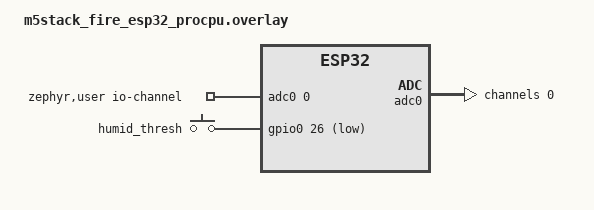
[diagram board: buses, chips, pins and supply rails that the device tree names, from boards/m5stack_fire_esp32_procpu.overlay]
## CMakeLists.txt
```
# Copyright (c) 2026 Lenka Koskova Triskova
#
# SPDX-License-Identifier: Apache-2.0
# https://www.apache.org/licenses/LICENSE-2.0

cmake_minimum_required(VERSION 3.20.0)

find_package(Zephyr REQUIRED HINTS $ENV{ZEPHYR_BASE})
project(humidity)

target_sources(app PRIVATE src/main.c)
```

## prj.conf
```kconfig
# Copyright (c) 2026 Lenka Koskova Triskova
#
# SPDX-License-Identifier: Apache-2.0
# https://www.apache.org/licenses/LICENSE-2.0

CONFIG_LOG=y
CONFIG_SHELL=y

# Unit Earth probe: no Zephyr sensor driver exists for it, so this reads
# the ADC and GPIO directly instead of going through CONFIG_SENSOR like
# 09-gyroscope does.
CONFIG_ADC=y

# Sampling thread publishes readings here; the logging thread is just
# one subscriber among however many you add.
CONFIG_ZBUS=y
```

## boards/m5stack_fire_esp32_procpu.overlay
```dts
/*
 * Copyright (c) 2026 Lenka Koskova Triskova
 *
 * SPDX-License-Identifier: Apache-2.0
 * https://www.apache.org/licenses/LICENSE-2.0
 */

/*
 * M5Stack "Unit Earth" analog soil/humidity probe, on Grove Port B:
 *
 *   - an analog reading on ADC1 channel 0 (Port B's D0 pin, GPIO36)
 *   - a digital wet/dry threshold output on Port B's D1 pin (&gpio0 26)
 *
 * Neither is defined by this board's own Zephyr devicetree - there is
 * no discrete sensor chip here (just a resistive probe plus a
 * comparator on the breakout board), so there is no Zephyr sensor
 * driver either: this is read directly via the ADC and GPIO APIs,
 * unlike 09-gyroscope's onboard MPU6886 which has a real driver.
 *
 * Per M5Stack's own official docs and ESP-IDF's adc_channel.h
 * (ADC1_CHANNEL_0_GPIO_NUM 36), Port B's D0 pin is GPIO36 = ADC1
 * channel 0.
 */

#include <zephyr/dt-bindings/adc/adc.h>
#include <zephyr/dt-bindings/input/input-event-codes.h>

/ {
	aliases {
		thresh = &humid_thresh;
	};

	zephyr,user {
		io-channels = <&adc0 0>;
	};

	/* "gpio-keys" is just the binding whose child-binding declares
	 * "gpios" as a phandle-array - a bare node with no compatible at
	 * all does not get that property type recognized, and
	 * GPIO_DT_SPEC_GET() then fails to compile. The input/key
	 * semantics of this binding are not used here - the pin is read
	 * directly as a plain GPIO in src/main.c, not through the input
	 * subsystem.
	 */
	humid_thresh_grp: humid_thresh_grp {
		compatible = "gpio-keys";

		humid_thresh: humid_thresh {
			/* ESP32's GPIO controller takes exactly one flags
			 * cell (#gpio-cells = <2>: pin, flags) - OR the
			 * flags together, don't list them as separate cells.
			 */
			gpios = <&gpio0 26 (GPIO_ACTIVE_LOW | GPIO_PULL_DOWN)>;
			/* Required by this binding's driver, but unused -
			 * this pin is read directly in src/main.c, never
			 * through the input subsystem.
			 */
			zephyr,code = <INPUT_KEY_9>;
		};
	};
};

&adc0 {
	compatible = "espressif,esp32-adc";
	status = "okay";
	#address-cells = <1>;
	#size-cells = <0>;

	channel0: channel@0 {
		status = "okay";
		reg = <0>;
		zephyr,gain = "ADC_GAIN_1_4";
		zephyr,reference = "ADC_REF_INTERNAL";
		zephyr,acquisition-time = <ADC_ACQ_TIME_DEFAULT>;
		/* Required - the ESP32 ADC driver rejects resolution 0,
		 * the default if left unset. 12-bit is this chip's max.
		 */
		zephyr,resolution = <12>;
	};
};

/* Not used by this app. */
&speaker {
	status = "disabled";
};
```

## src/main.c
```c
/*
 * Copyright (c) 2026 Lenka Koskova Triskova
 *
 * SPDX-License-Identifier: Apache-2.0
 * https://www.apache.org/licenses/LICENSE-2.0
 */

#include <zephyr/kernel.h>
#include <zephyr/device.h>
#include <zephyr/devicetree.h>
#include <zephyr/drivers/adc.h>
#include <zephyr/drivers/gpio.h>
#include <zephyr/zbus/zbus.h>
#include <zephyr/logging/log.h>

LOG_MODULE_REGISTER(main);

#if !DT_NODE_EXISTS(DT_PATH(zephyr_user)) || \
	!DT_NODE_HAS_PROP(DT_PATH(zephyr_user), io_channels)
#error "No suitable devicetree overlay specified - see boards/m5stack_fire_esp32_procpu.overlay"
#endif

#define SAMPLE_INTERVAL K_SECONDS(2)

/* Calibrate these against your own probe: watch the "raw=" value in the
 * log output in open air and in wet soil, and set these two to match.
 */
#define ADC_MIN_VALUE 830
#define ADC_MAX_VALUE 1940
#define PCT_MIN       0
#define PCT_MAX       100

struct humidity_msg {
	int16_t raw;
	int16_t percent;
	bool threshold_high;
};

/* The channel is shared between the sampling thread (publisher, below)
 * and whoever wants the readings (observers) - here just
 * humidity_log_sub, but any thread can later subscribe without the
 * sampling thread ever changing. Same template as 09-gyroscope.
 */
ZBUS_CHAN_DEFINE(humidity_chan,
		 struct humidity_msg,
		 NULL,
		 NULL,
		 ZBUS_OBSERVERS(humidity_log_sub),
		 ZBUS_MSG_INIT(0)
);

/* Subscriber, not listener: it gets its own thread and message queue,
 * so a slow or blocking reaction here can never stall the sampling
 * thread - see 09-gyroscope's README for why this is the default for
 * every observer in this course, sensors and actuators alike.
 */
ZBUS_SUBSCRIBER_DEFINE(humidity_log_sub, 4);

static void humidity_log_thread(void *p1, void *p2, void *p3)
{
	ARG_UNUSED(p1);
	ARG_UNUSED(p2);
	ARG_UNUSED(p3);

	const struct zbus_channel *chan;

	while (!zbus_sub_wait(&humidity_log_sub, &chan, K_FOREVER)) {
		struct humidity_msg msg;

		if (chan != &humidity_chan) {
			continue;
		}

		zbus_chan_read(&humidity_chan, &msg, K_MSEC(100));

		LOG_INF("humidity: %d%% (raw=%d, threshold %s)",
			msg.percent, msg.raw, msg.threshold_high ? "HIGH" : "LOW");
	}
}

#define HUMIDITY_LOG_STACK_SIZE 1024
#define HUMIDITY_LOG_PRIORITY   5

K_THREAD_DEFINE(humidity_log_tid, HUMIDITY_LOG_STACK_SIZE, humidity_log_thread,
		 NULL, NULL, NULL, HUMIDITY_LOG_PRIORITY, 0, 0);

static void humidity_sampling_thread(void *p1, void *p2, void *p3)
{
	ARG_UNUSED(p1);
	ARG_UNUSED(p2);
	ARG_UNUSED(p3);

	static const struct adc_dt_spec probe = ADC_DT_SPEC_GET(DT_PATH(zephyr_user));
	static const struct gpio_dt_spec thresh = GPIO_DT_SPEC_GET(DT_ALIAS(thresh), gpios);

	if (!adc_is_ready_dt(&probe)) {
		LOG_ERR("ADC device is not ready");
		return;
	}
	if (adc_channel_setup_dt(&probe) < 0) {
		LOG_ERR("Failed to set up ADC channel");
		return;
	}
	if (!device_is_ready(thresh.port)) {
		LOG_ERR("Threshold GPIO is not ready");
		return;
	}
	if (gpio_pin_configure_dt(&thresh, GPIO_INPUT) < 0) {
		LOG_ERR("Failed to configure threshold GPIO");
		return;
	}

	/* Only the buffer pointer changes per sample (filled in below) -
	 * everything adc_sequence_init_dt() derives from the devicetree
	 * (channel mask, resolution, oversampling) is fixed, so it only
	 * needs to run once, not on every iteration.
	 */
	int16_t raw;
	struct adc_sequence sequence = {
		.buffer = &raw,
		.buffer_size = sizeof(raw),
	};

	adc_sequence_init_dt(&probe, &sequence);

	while (1) {
		if (adc_read_dt(&probe, &sequence) < 0) {
			LOG_ERR("ADC read failed");
			k_sleep(SAMPLE_INTERVAL);
			continue;
		}

		int32_t pct = PCT_MAX - (raw - ADC_MIN_VALUE) *
				(PCT_MAX - PCT_MIN) / (ADC_MAX_VALUE - ADC_MIN_VALUE);
		pct = CLAMP(pct, PCT_MIN, PCT_MAX);

		struct humidity_msg msg = {
			.raw = raw,
			.percent = (int16_t)pct,
			.threshold_high = gpio_pin_get_dt(&thresh) == 1,
		};

		/* Publish and move on - a slow or missing subscriber never
		 * blocks sampling for longer than this timeout.
		 */
		zbus_chan_pub(&humidity_chan, &msg, K_MSEC(100));

		k_sleep(SAMPLE_INTERVAL);
	}
}

#define HUMIDITY_SAMPLE_STACK_SIZE 1024
#define HUMIDITY_SAMPLE_PRIORITY   5

K_THREAD_DEFINE(humidity_sample_tid, HUMIDITY_SAMPLE_STACK_SIZE, humidity_sampling_thread,
		 NULL, NULL, NULL, HUMIDITY_SAMPLE_PRIORITY, 0, 0);

int main(void)
{
	/* Everything happens in the sampling thread and the logging
	 * subscriber, both started above via K_THREAD_DEFINE.
	 */
	return 0;
}
```
